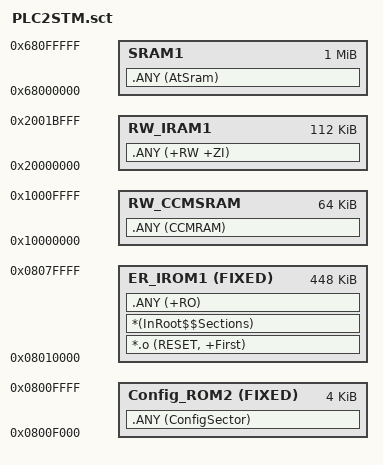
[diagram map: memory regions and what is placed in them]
; *************************************************************
; *** Scatter-Loading Description File generated by uVision ***
; *************************************************************

LR_IROM1 0x0800F000 0x00080000  {    ; load region size_region

  Config_ROM2 0x0800F000 FIXED 0x00001000  {  ;指定根区，即load address = execution address，执行加载同在flash中的貌似必须指定根区
   .ANY (ConfigSector)
  }
 
  ER_IROM1 0x08010000 FIXED 0x00070000  {  ; load address = execution address
   *.o (RESET, +First)
   *(InRoot$$Sections)
   .ANY (+RO)
  }
  
  RW_IRAM1 0x20000000 0x0001C000  {  ; RW data
   .ANY (+RW +ZI)
  }

  RW_CCMSRAM 0x10000000 0x00010000  {  ; RW data
   .ANY (CCMRAM)
  }

  SRAM1 0x68000000    0x100000{  
   .ANY (AtSram)
  }  
}


